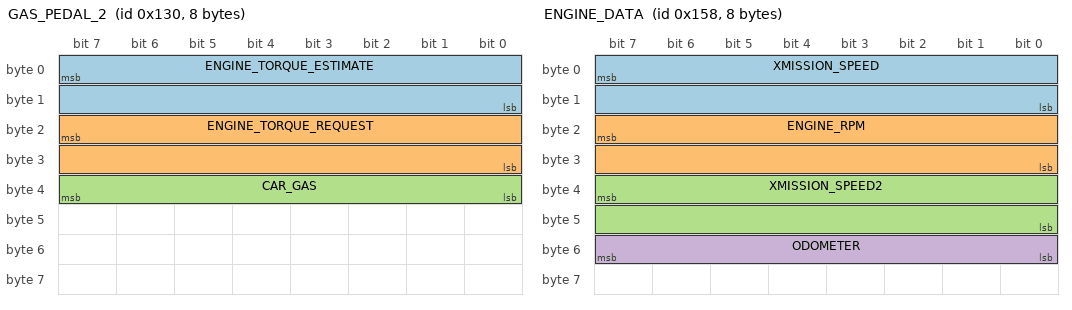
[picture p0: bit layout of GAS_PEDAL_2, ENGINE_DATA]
BO_ 304 GAS_PEDAL_2: 8 PCM
 SG_ ENGINE_TORQUE_ESTIMATE : 7|16@0- (1,0) [-1000|1000] "Nm" EON
 SG_ ENGINE_TORQUE_REQUEST : 23|16@0- (1,0) [-1000|1000] "Nm" EON
 SG_ CAR_GAS : 39|8@0+ (1,0) [0|255] "" EON

BO_ 316 GAS_PEDAL: 8 PCM
 SG_ CAR_GAS : 39|8@0+ (1,0) [0|255] "" EON
 SG_ COUNTER : 61|2@0+ (1,0) [0|3] "" EON

BO_ 344 ENGINE_DATA: 8 PCM
 SG_ XMISSION_SPEED : 7|16@0+ (0.01,0) [0|250] "kph" EON
 SG_ ENGINE_RPM : 23|16@0+ (1,0) [0|15000] "rpm" EON
 SG_ XMISSION_SPEED2 : 39|16@0+ (0.01,0) [0|250] "kph" EON
 SG_ ODOMETER : 55|8@0+ (10,0) [0|2550] "m" XXX

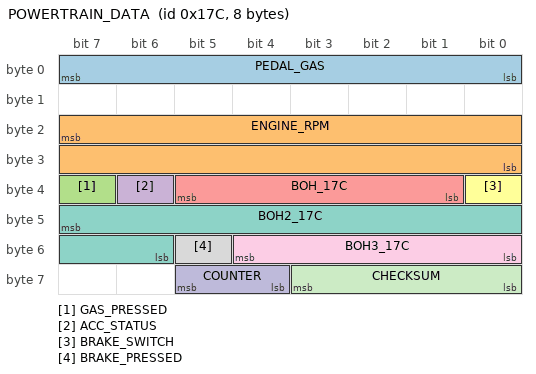
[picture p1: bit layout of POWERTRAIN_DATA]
BO_ 380 POWERTRAIN_DATA: 8 PCM
 SG_ PEDAL_GAS : 7|8@0+ (1,0) [0|255] "" EON
 SG_ ENGINE_RPM : 23|16@0+ (1,0) [0|15000] "rpm" EON
 SG_ GAS_PRESSED : 39|1@0+ (1,0) [0|1] "" EON
 SG_ ACC_STATUS : 38|1@0+ (1,0) [0|1] "" EON
 SG_ BOH_17C : 37|5@0+ (1,0) [0|1] "" EON
 SG_ BRAKE_SWITCH : 32|1@0+ (1,0) [0|1] "" EON
 SG_ BOH2_17C : 47|10@0+ (1,0) [0|1] "" EON
 SG_ BRAKE_PRESSED : 53|1@0+ (1,0) [0|1] "" EON
 SG_ BOH3_17C : 52|5@0+ (1,0) [0|1] "" EON
 SG_ COUNTER : 61|2@0+ (1,0) [0|3] "" EON
 SG_ CHECKSUM : 59|4@0+ (1,0) [0|15] "" EON
